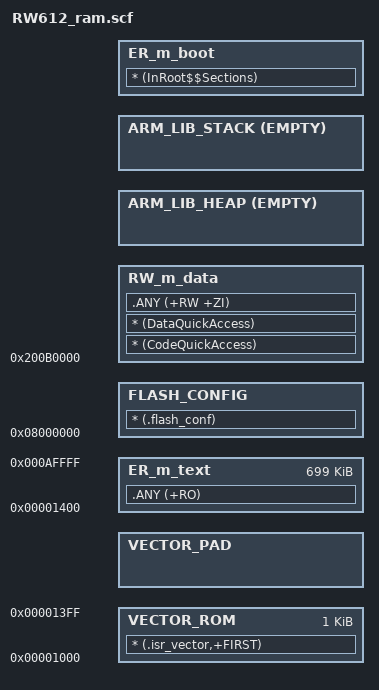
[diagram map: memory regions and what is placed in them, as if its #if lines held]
#!armclang --target=arm-arm-none-eabi -march=armv8-m.main -E -x c
/*
** ###################################################################
**     Processors:          RW612ETA2I
**                          RW612HNA2I
**                          RW612UKA2I
**
**     Compiler:            Keil ARM C/C++ Compiler
**     Reference manual:    RW61X User manual Rev. 0.95, June 2022
**     Version:             rev. 1.0, 2021-03-16
**     Build:               b231201
**
**     Abstract:
**         Linker file for the Keil ARM C/C++ Compiler
**
**     Copyright 2016 Freescale Semiconductor, Inc.
**     Copyright 2016-2023 NXP
**     SPDX-License-Identifier: BSD-3-Clause
**
**     http:                 www.nxp.com
**     mail:                 support@nxp.com
**
** ###################################################################
*/


/* Sizes */
#if (defined(__stack_size__))
  #define Stack_Size                   __stack_size__
#else
  #define Stack_Size                   0x0400
#endif

#if (defined(__heap_size__))
  #define Heap_Size                    __heap_size__
#else
  #define Heap_Size                    0x0400
#endif

#define  m_flash_start                 0x08000000

#define  m_boot_interrupts_start       0x08001000

#define  m_interrupts_start            0x00001000
#define  m_interrupts_size             0x00000400

#define  m_text_start                  0x00001400
#define  m_text_size                   0x000AEC00

#define  m_data_start                  0x200B0000
#define  m_data_size                   0x00080000


LR_m_flash_conf m_flash_start m_boot_interrupts_start-m_flash_start {
  FLASH_CONFIG +0 { ; load address = execution address
    * (.flash_conf)
  }
}

LR_m_interrupts m_boot_interrupts_start m_interrupts_size+m_text_size {
  VECTOR_ROM m_interrupts_start m_interrupts_size {
    * (.isr_vector,+FIRST)
  }
  VECTOR_PAD +0 FILL 0x0 m_text_start-ImageLimit(VECTOR_ROM) {
  }
  ER_m_text m_text_start m_text_size {
    .ANY (+RO)
  }

  RW_m_data m_data_start ALIGN 4 m_data_size-Stack_Size-Heap_Size { ; RW data
    * (CodeQuickAccess)
    * (DataQuickAccess)
    .ANY (+RW +ZI)
  }

  ARM_LIB_HEAP +0 EMPTY Heap_Size {    ; Heap region growing up
  }
  ARM_LIB_STACK m_data_start+m_data_size EMPTY -Stack_Size { ; Stack region growing down
  }
}

LR_m_boot +0 {
  ER_m_boot +0 { ; load address = execution address
    * (InRoot$$Sections)
  }
}
